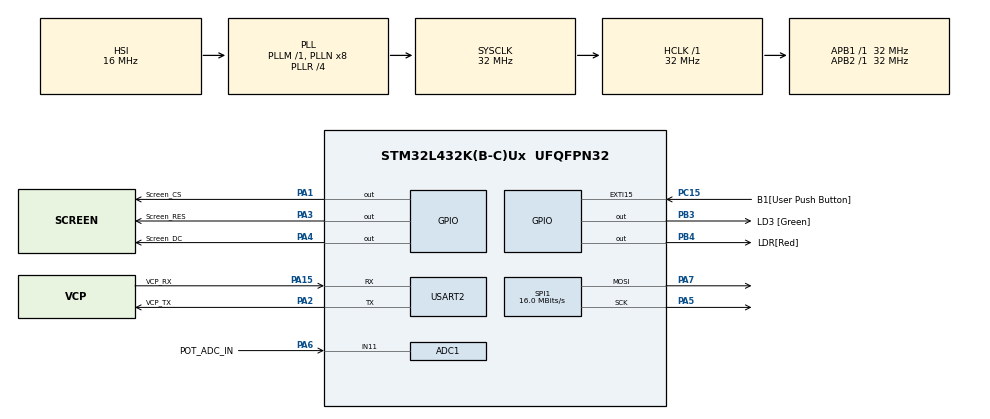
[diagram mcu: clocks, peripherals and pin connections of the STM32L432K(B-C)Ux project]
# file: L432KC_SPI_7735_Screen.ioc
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ADC1.Channel-1\#ChannelRegularConversion=ADC_CHANNEL_11
ADC1.NbrOfConversionFlag=1
ADC1.OffsetNumber-1\#ChannelRegularConversion=ADC_OFFSET_NONE
ADC1.Rank-1\#ChannelRegularConversion=1
ADC1.SamplingTime-1\#ChannelRegularConversion=ADC_SAMPLETIME_640CYCLES_5
ADC1.master=1
Mcu.Family=STM32L4
Mcu.Name=STM32L432K(B-C)Ux
Mcu.Package=UFQFPN32
NVIC.EXTI15_10_IRQn=true\:0\:0\:false\:false\:true\:true\:true\:true
NVIC.PriorityGroup=NVIC_PRIORITYGROUP_4
PA1.GPIO_Label=Screen_CS
PA1.Signal=GPIO_Output
PA13\ (JTMS-SWDIO).GPIO_Label=SWDIO
PA13\ (JTMS-SWDIO).Mode=Serial_Wire
PA13\ (JTMS-SWDIO).Signal=SYS_JTMS-SWDIO
PA14\ (JTCK-SWCLK).GPIO_Label=SWCLK
PA14\ (JTCK-SWCLK).Mode=Serial_Wire
PA14\ (JTCK-SWCLK).Signal=SYS_JTCK-SWCLK
PA15\ (JTDI).GPIO_Label=VCP_RX
PA15\ (JTDI).Mode=Asynchronous
PA15\ (JTDI).Signal=USART2_RX
PA2.GPIO_Label=VCP_TX
PA2.Mode=Asynchronous
PA2.Signal=USART2_TX
PA3.GPIO_Label=Screen_RES
PA3.Signal=GPIO_Output
PA4.GPIO_Label=Screen_DC
PA4.Signal=GPIO_Output
PA5.Mode=TX_Only_Simplex_Unidirect_Master
PA5.Signal=SPI1_SCK
PA6.GPIO_Label=POT_ADC_IN
PA6.Signal=ADCx_IN11
PA7.Mode=TX_Only_Simplex_Unidirect_Master
PA7.Signal=SPI1_MOSI
PB3\ (JTDO-TRACESWO).GPIO_Label=LD3 [Green]
PB3\ (JTDO-TRACESWO).Signal=GPIO_Output
PB4\ (NJTRST).GPIO_Label=LDR[Red]
PB4\ (NJTRST).Signal=GPIO_Output
PC15-OSC32_OUT\ (PC15).GPIO_Label=B1[User Push Button]
PC15-OSC32_OUT\ (PC15).GPIO_ModeDefaultEXTI=GPIO_MODE_IT_RISING_FALLING
PC15-OSC32_OUT\ (PC15).GPIO_PuPd=GPIO_PULLUP
PC15-OSC32_OUT\ (PC15).Signal=GPXTI15
ProjectManager.HeapSize=0x200
ProjectManager.StackSize=0x400
ProjectManager.TargetToolchain=STM32CubeIDE
RCC.ADCFreq_Value=64000000
RCC.AHBFreq_Value=32000000
RCC.APB1Freq_Value=32000000
RCC.APB1TimFreq_Value=32000000
RCC.APB2Freq_Value=32000000
RCC.APB2TimFreq_Value=32000000
RCC.CortexFreq_Value=32000000
RCC.HCLKFreq_Value=32000000
RCC.HSE_VALUE=8000000
RCC.HSI16_VALUE=16000000
RCC.HSI48_VALUE=48000000
RCC.HSI_VALUE=16000000
RCC.LSE_VALUE=32768
RCC.MSI_VALUE=4000000
RCC.PLLMUL=RCC_PLLMUL_4
RCC.PLLR=RCC_PLLR_DIV4
RCC.PLLSourceVirtual=RCC_PLLSOURCE_HSI
RCC.SYSCLKFreq_VALUE=32000000
RCC.SYSCLKSource=RCC_SYSCLKSOURCE_PLLCLK
RCC.USBFreq_Value=64000000
RCC.VCOOutputFreq_Value=128000000
SH.ADCx_IN11.0=ADC1_IN11,IN11-Single-Ended
SPI1.BaudRatePrescaler=SPI_BAUDRATEPRESCALER_2
SPI1.CalculateBaudRate=16.0 MBits/s
SPI1.DataSize=SPI_DATASIZE_8BIT
SPI1.Direction=SPI_DIRECTION_2LINES
SPI1.Mode=SPI_MODE_MASTER
SPI1.VirtualType=VM_MASTER
USART2.SwapParam=ADVFEATURE_SWAP_ENABLE
USART2.VirtualMode-Asynchronous=VM_ASYNC
board=NUCLEO-L432KC

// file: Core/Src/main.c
/* USER CODE BEGIN Header */
/**
 ******************************************************************************
 * @file           : main.c
 * @brief          : Main program body
 ******************************************************************************
 * @attention
 *
 * Copyright (c) 2025 STMicroelectronics.
 * All rights reserved.
 *
 * This software is licensed under terms that can be found in the LICENSE file
 * in the root directory of this software component.
 * If no LICENSE file comes with this software, it is provided AS-IS.
 *
 ******************************************************************************
 */
/* USER CODE END Header */
#include "main.h"
#include "adc.h"
#include "spi.h"
#include "usart.h"
#include "gpio.h"

/* USER CODE BEGIN Includes */
#include "menu.h"
/* USER CODE END Includes */

void SystemClock_Config(void);

int main(void)
{

  /* MCU Configuration--------------------------------------------------------*/

  /* Reset of all peripherals, Initializes the Flash interface and the Systick. */
  HAL_Init();

  /* Configure the system clock */
  SystemClock_Config();

  /* Initialize all configured peripherals */
  MX_GPIO_Init();
  MX_USART2_UART_Init();
  MX_ADC1_Init();
  MX_SPI1_Init();

  /* Infinite loop */
  /* USER CODE BEGIN WHILE */
	ST7735_Init();
	ST7735_InvertColors(0);
	menu_demo();
	drawMenu();

	while (1)
	{
			// Mode menu -> Attente d'une interruption
			HAL_PWR_EnterSLEEPMode(PWR_MAINREGULATOR_ON, PWR_SLEEPENTRY_WFI);

    /* USER CODE END WHILE */

	}
}

void SystemClock_Config(void)
{
  RCC_OscInitTypeDef RCC_OscInitStruct = {0};
  RCC_ClkInitTypeDef RCC_ClkInitStruct = {0};

  /** Configure the main internal regulator output voltage
  */
  if (HAL_PWREx_ControlVoltageScaling(PWR_REGULATOR_VOLTAGE_SCALE1) != HAL_OK)
  {
    Error_Handler();
  }

  /** Initializes the RCC Oscillators according to the specified parameters
  * in the RCC_OscInitTypeDef structure.
  */
  RCC_OscInitStruct.OscillatorType = RCC_OSCILLATORTYPE_HSI;
  RCC_OscInitStruct.HSIState = RCC_HSI_ON;
  RCC_OscInitStruct.HSICalibrationValue = RCC_HSICALIBRATION_DEFAULT;
  RCC_OscInitStruct.PLL.PLLState = RCC_PLL_ON;
  RCC_OscInitStruct.PLL.PLLSource = RCC_PLLSOURCE_HSI;
  RCC_OscInitStruct.PLL.PLLM = 1;
  RCC_OscInitStruct.PLL.PLLN = 8;
  RCC_OscInitStruct.PLL.PLLP = RCC_PLLP_DIV7;
  RCC_OscInitStruct.PLL.PLLQ = RCC_PLLQ_DIV2;
  RCC_OscInitStruct.PLL.PLLR = RCC_PLLR_DIV4;
  if (HAL_RCC_OscConfig(&RCC_OscInitStruct) != HAL_OK)
  {
    Error_Handler();
  }

  /** Initializes the CPU, AHB and APB buses clocks
  */
  RCC_ClkInitStruct.ClockType = RCC_CLOCKTYPE_HCLK|RCC_CLOCKTYPE_SYSCLK
                              |RCC_CLOCKTYPE_PCLK1|RCC_CLOCKTYPE_PCLK2;
  RCC_ClkInitStruct.SYSCLKSource = RCC_SYSCLKSOURCE_PLLCLK;
  RCC_ClkInitStruct.AHBCLKDivider = RCC_SYSCLK_DIV1;
  RCC_ClkInitStruct.APB1CLKDivider = RCC_HCLK_DIV1;
  RCC_ClkInitStruct.APB2CLKDivider = RCC_HCLK_DIV1;

  if (HAL_RCC_ClockConfig(&RCC_ClkInitStruct, FLASH_LATENCY_1) != HAL_OK)
  {
    Error_Handler();
  }
}

void Error_Handler(void)
{
	__disable_irq();
	while (1)
	{
	}
}
